# max32680 register map
Vendor: Maxim-Integrated; Series: ARMCM4; File version: 1.1
CPU: CM4 r2p1, little endian, MPU, FPU, 3 interrupt priority bits
Registers are 32-bit, read-write, reset 0x0 unless marked. A register's access mark holds for its fields unless they carry their own. Offsets are from the block's base; [hi:lo] are bit positions; {n}, {i} and the like mark numbered series.

## RTC — Real Time Clock and Alarm.
Base 0x40006000
0x00 SEC reset not defined — RTC Second Counter. This register contains the 32-bit second counter.
  [31:0] SEC — Seconds Counter.
0x04 SSEC reset not defined — RTC Sub-second Counter. This counter increments at 256Hz. RTC_SEC is incremented when this register rolls over from 0xFF to 0x00.
  [11:0] SSEC — Sub-Seconds Counter (12-bit).
0x08 TODA reset not defined — Time-of-day Alarm.
  [19:0] TOD_ALARM
0x0C SSECA reset not defined — RTC sub-second alarm. This register contains the reload value for the sub-second alarm.
  [31:0] SSEC_ALARM — This register contains the reload value for the sub-second alarm.
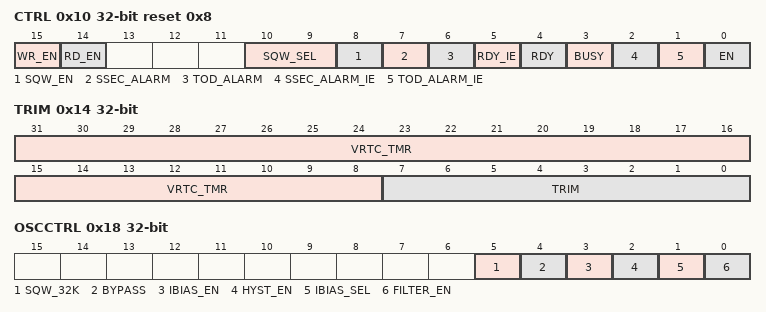
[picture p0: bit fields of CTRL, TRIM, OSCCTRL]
0x10 CTRL reset 0x8 (reset mask 0xFFFFFF38) — RTC Control Register.
  [15] WR_EN — Write Enable. This register bit serves as a protection mechanism against unintentional writes to critical RTC bits.
    0=inactive (Not active); 1=Pending (Active)
  [14] RD_EN — Asynchronous Counter Read Enable.
  [10:9] SQW_SEL — Frequency Output Selection. When SQE=1, these bits specify the output frequency on the SQW pin.
    0=freq1Hz (1 Hz (Compensated).); 1=freq512Hz (512 Hz (Compensated).); 2=freq4KHz (4 KHz.); 3=clkDiv8 (RTC Input Clock / 8.)
  [8] SQW_EN — Square Wave Output Enable.
    0=inactive (Not active); 1=Pending (Active)
  [7] SSEC_ALARM ro — Sub-second Alarm Interrupt Flag. This alarm is qualified as wake-up source to the processor.
    0=inactive (Not active); 1=Pending (Active)
  [6] TOD_ALARM ro — Time-of-Day Alarm Interrupt Flag. This alarm is qualified as wake-up source to the processor.
    0=inactive (Not active); 1=Pending (Active)
  [5] RDY_IE — RTC Ready Interrupt Enable.
    0=dis (Disable.); 1=en (Enable.)
  [4] RDY — RTC Ready. This bit is set to 1 by hardware when the RTC count registers update. It can be cleared to 0 by software at any time. It will also be cleared to 0 by hardware just prior to an update of the RTC count register.
    0=busy (Register has not updated.); 1=ready
  [3] BUSY ro — RTC Busy. This bit is set to 1 by hardware when changes to RTC registers required a synchronized version of the register to be in place. This bit is automatically cleared by hardware.
    0=idle; 1=busy
  [2] SSEC_ALARM_IE — Alarm Sub-second Interrupt Enable. Change to this bit is effective only after BUSY is cleared from 1 to 0.
    0=dis (Disable.); 1=en (Enable.)
  [1] TOD_ALARM_IE — Alarm Time-of-Day Interrupt Enable. Change to this bit is effective only after BUSY is cleared from 1 to 0.
    0=dis (Disable.); 1=en (Enable.)
  [0] EN — Real Time Clock Enable. This bit enables the Real Time Clock. This bit can only be written when WE=1 and BUSY =0. Change to this bit is effective only after BUSY is cleared from 1 to 0.
    0=dis (Disable.); 1=en (Enable.)
0x14 TRIM reset not defined — RTC Trim Register.
  [31:8] VRTC_TMR — VBAT Timer Value. When RTC is running off of VBAT, this field is incremented every 32 seconds.
  [7:0] TRIM — RTC Trim. This register contains the 2's complement value that specifies the trim resolution. Each increment or decrement of the bit adds or subtracts 1ppm at each 4KHz clock value, with a maximum correction of +/- 127ppm.
0x18 OSCCTRL reset not defined — RTC Oscillator Control Register.
  [5] SQW_32K — RTC 32kHz Square Wave Output
  [4] BYPASS — RTC Crystal Bypass
  [3] IBIAS_EN — Enables higher 4x,2x current modes.
  [2] HYST_EN — Enables high current hysteresis buffer.
  [1] IBIAS_SEL — If IBIAS_EN is 1, selects 4x,2x mode.
  [0] FILTER_EN — Enables analog deglitch filter.

## SEMA — The Semaphore peripheral allows multiple cores in a system to cooperate when accessing shred resources. The peripheral contains eight semaphores that can be atomically set and cleared. It is left to the discretion of the software architect to decide how and when the semaphores are used and how they are allocated. Existing hardware does not have to be modified for this type of cooperative sharing, and the use of semaphores is exclusively within the software domain.
Base 0x4003E000
{0x0+4i} SEMAPHORES[{i}] (i=0..7) — Read to test and set, returns prior value. Write 0 to clear semaphore.
  [0] sema
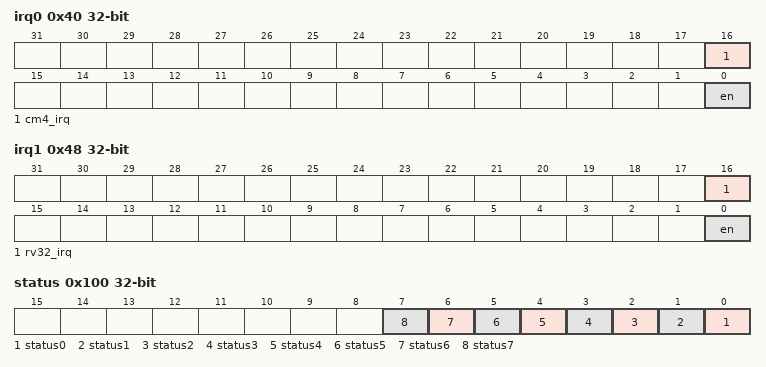
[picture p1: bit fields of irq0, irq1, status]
0x40 irq0 — Semaphore IRQ0 register.
  [16] cm4_irq, [0] en
0x44 mail0 — Semaphore Mailbox 0 register.
  [31:0] data
0x48 irq1 — Semaphore IRQ1 register.
  [16] rv32_irq, [0] en
0x4C mail1 — Semaphore Mailbox 1 register.
  [31:0] data
0x100 status — Semaphore status bits. 0 indicates the semaphore is free, 1 indicates taken.
  [n] status{n} (n=0..7)
